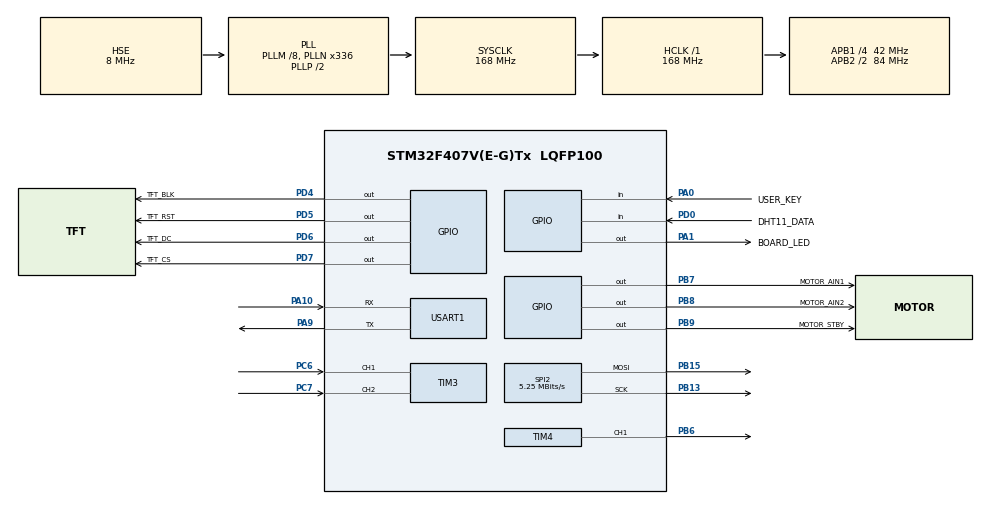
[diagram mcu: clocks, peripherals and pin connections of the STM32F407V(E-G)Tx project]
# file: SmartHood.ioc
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FREERTOS.Tasks01=defaultTask,24,256,StartDefaultTask,Default,NULL,Dynamic,NULL,NULL;sensorTask,24,256,StartSensorTask,Default,NULL,Dynamic,NULL,NULL;motorTask,24,256,StartMotorTask,Default,NULL,Dynamic,NULL,NULL
FREERTOS.configTOTAL_HEAP_SIZE=32768
Mcu.Family=STM32F4
Mcu.Name=STM32F407V(E-G)Tx
Mcu.Package=LQFP100
NVIC.PriorityGroup=NVIC_PRIORITYGROUP_4
NVIC.TIM6_DAC_IRQn=true\:15\:0\:false\:false\:true\:false\:false\:true\:true
NVIC.TimeBase=TIM6_DAC_IRQn
NVIC.TimeBaseIP=TIM6
PA0-WKUP.GPIO_Label=USER_KEY
PA0-WKUP.GPIO_PuPd=GPIO_PULLDOWN
PA0-WKUP.Signal=GPIO_Input
PA1.GPIO_Label=BOARD_LED
PA1.PinState=GPIO_PIN_SET
PA1.Signal=GPIO_Output
PA10.Mode=Asynchronous
PA10.Signal=USART1_RX
PA13.Mode=Serial_Wire
PA13.Signal=SYS_JTMS-SWDIO
PA14.Mode=Serial_Wire
PA14.Signal=SYS_JTCK-SWCLK
PA9.Mode=Asynchronous
PA9.Signal=USART1_TX
PB13.Mode=TX_Only_Simplex_Unidirect_Master
PB13.Signal=SPI2_SCK
PB15.Mode=TX_Only_Simplex_Unidirect_Master
PB15.Signal=SPI2_MOSI
PB6.Signal=S_TIM4_CH1
PB7.GPIO_Label=MOTOR_AIN1
PB7.Signal=GPIO_Output
PB8.GPIO_Label=MOTOR_AIN2
PB8.Signal=GPIO_Output
PB9.GPIO_Label=MOTOR_STBY
PB9.Signal=GPIO_Output
PC6.GPIO_PuPd=GPIO_PULLUP
PC6.Signal=S_TIM3_CH1
PC7.GPIO_PuPd=GPIO_PULLUP
PC7.Signal=S_TIM3_CH2
PD0.GPIO_Label=DHT11_DATA
PD0.GPIO_PuPd=GPIO_PULLUP
PD0.Signal=GPIO_Input
PD4.GPIO_Label=TFT_BLK
PD4.PinState=GPIO_PIN_RESET
PD4.Signal=GPIO_Output
PD5.GPIO_Label=TFT_RST
PD5.PinState=GPIO_PIN_SET
PD5.Signal=GPIO_Output
PD6.GPIO_Label=TFT_DC
PD6.PinState=GPIO_PIN_RESET
PD6.Signal=GPIO_Output
PD7.GPIO_Label=TFT_CS
PD7.PinState=GPIO_PIN_SET
PD7.Signal=GPIO_Output
PH0-OSC_IN.Mode=HSE-External-Oscillator
PH0-OSC_IN.Signal=RCC_OSC_IN
PH1-OSC_OUT.Mode=HSE-External-Oscillator
PH1-OSC_OUT.Signal=RCC_OSC_OUT
ProjectManager.HeapSize=0x400
ProjectManager.StackSize=0x800
ProjectManager.TargetToolchain=MDK-ARM V5.32
RCC.48MHZClocksFreq_Value=84000000
RCC.AHBFreq_Value=168000000
RCC.APB1CLKDivider=RCC_HCLK_DIV4
RCC.APB1Freq_Value=42000000
RCC.APB1TimFreq_Value=84000000
RCC.APB2CLKDivider=RCC_HCLK_DIV2
RCC.APB2Freq_Value=84000000
RCC.APB2TimFreq_Value=168000000
RCC.CortexFreq_Value=168000000
RCC.HCLKFreq_Value=168000000
RCC.HSE_VALUE=8000000
RCC.HSI_VALUE=16000000
RCC.LSE_VALUE=32768
RCC.PLLM=8
RCC.PLLN=336
RCC.PLLSourceVirtual=RCC_PLLSOURCE_HSE
RCC.SYSCLKFreq_VALUE=168000000
RCC.SYSCLKSource=RCC_SYSCLKSOURCE_PLLCLK
RCC.VCOOutputFreq_Value=336000000
SH.S_TIM3_CH1.0=TIM3_CH1,Encoder_Interface
SH.S_TIM3_CH2.0=TIM3_CH2,Encoder_Interface
SH.S_TIM4_CH1.0=TIM4_CH1,PWM Generation1 CH1
SPI2.BaudRatePrescaler=SPI_BAUDRATEPRESCALER_8
SPI2.CalculateBaudRate=5.25 MBits/s
SPI2.Direction=SPI_DIRECTION_2LINES
SPI2.Mode=SPI_MODE_MASTER
SPI2.VirtualType=VM_MASTER
TIM3.EncoderMode=TIM_ENCODERMODE_TI12
TIM3.IC1Filter=4
TIM3.IC2Filter=4
TIM4.Channel-PWM\ Generation1\ CH1=TIM_CHANNEL_1
TIM4.Period=4199
TIM5.Prescaler=83
USART1.VirtualMode=VM_ASYNC
VP_FREERTOS_VS_CMSIS_V2.Mode=CMSIS_V2
VP_SYS_VS_tim6.Mode=TIM6
VP_TIM5_VS_ClockSourceINT.Mode=Internal
board=custom

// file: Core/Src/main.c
/* USER CODE BEGIN Header */
/**
  ******************************************************************************
  * @file           : main.c
  * @brief          : Main program body
  ******************************************************************************
  * @attention
  *
  * Copyright (c) 2026 STMicroelectronics.
  * All rights reserved.
  *
  * This software is licensed under terms that can be found in the LICENSE file
  * in the root directory of this software component.
  * If no LICENSE file comes with this software, it is provided AS-IS.
  *
  ******************************************************************************
  */
/* USER CODE END Header */
#include "main.h"
#include "cmsis_os.h"
#include "spi.h"
#include "tim.h"
#include "usart.h"
#include "gpio.h"

void SystemClock_Config(void);
void MX_FREERTOS_Init(void);

int main(void)
{

  /* MCU Configuration--------------------------------------------------------*/

  /* Reset of all peripherals, Initializes the Flash interface and the Systick. */
  HAL_Init();

  /* Configure the system clock */
  SystemClock_Config();

  /* Initialize all configured peripherals */
  MX_GPIO_Init();
  MX_USART1_UART_Init();
  MX_SPI2_Init();
  MX_TIM5_Init();
  MX_TIM4_Init();
  MX_TIM3_Init();

  /* Init scheduler */
  osKernelInitialize();  /* Call init function for freertos objects (in cmsis_os2.c) */
  MX_FREERTOS_Init();

  /* Start scheduler */
  osKernelStart();

  /* We should never get here as control is now taken by the scheduler */

  /* Infinite loop */
  while (1)
  {

  }
}

void SystemClock_Config(void)
{
  RCC_OscInitTypeDef RCC_OscInitStruct = {0};
  RCC_ClkInitTypeDef RCC_ClkInitStruct = {0};

  /** Configure the main internal regulator output voltage
  */
  __HAL_RCC_PWR_CLK_ENABLE();
  __HAL_PWR_VOLTAGESCALING_CONFIG(PWR_REGULATOR_VOLTAGE_SCALE1);

  /** Initializes the RCC Oscillators according to the specified parameters
  * in the RCC_OscInitTypeDef structure.
  */
  RCC_OscInitStruct.OscillatorType = RCC_OSCILLATORTYPE_HSE;
  RCC_OscInitStruct.HSEState = RCC_HSE_ON;
  RCC_OscInitStruct.PLL.PLLState = RCC_PLL_ON;
  RCC_OscInitStruct.PLL.PLLSource = RCC_PLLSOURCE_HSE;
  RCC_OscInitStruct.PLL.PLLM = 8;
  RCC_OscInitStruct.PLL.PLLN = 336;
  RCC_OscInitStruct.PLL.PLLP = RCC_PLLP_DIV2;
  RCC_OscInitStruct.PLL.PLLQ = 4;
  if (HAL_RCC_OscConfig(&RCC_OscInitStruct) != HAL_OK)
  {
    Error_Handler();
  }

  /** Initializes the CPU, AHB and APB buses clocks
  */
  RCC_ClkInitStruct.ClockType = RCC_CLOCKTYPE_HCLK|RCC_CLOCKTYPE_SYSCLK
                              |RCC_CLOCKTYPE_PCLK1|RCC_CLOCKTYPE_PCLK2;
  RCC_ClkInitStruct.SYSCLKSource = RCC_SYSCLKSOURCE_PLLCLK;
  RCC_ClkInitStruct.AHBCLKDivider = RCC_SYSCLK_DIV1;
  RCC_ClkInitStruct.APB1CLKDivider = RCC_HCLK_DIV4;
  RCC_ClkInitStruct.APB2CLKDivider = RCC_HCLK_DIV2;

  if (HAL_RCC_ClockConfig(&RCC_ClkInitStruct, FLASH_LATENCY_5) != HAL_OK)
  {
    Error_Handler();
  }
}

void HAL_TIM_PeriodElapsedCallback(TIM_HandleTypeDef *htim)
{
  if (htim->Instance == TIM6)
  {
    HAL_IncTick();
  }
}

void Error_Handler(void)
{
  __disable_irq();
  while (1)
  {
  }
}

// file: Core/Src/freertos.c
/* USER CODE BEGIN Header */
/**
  ******************************************************************************
  * File Name          : freertos.c
  * Description        : Code for freertos applications
  ******************************************************************************
  * @attention
  *
  * Copyright (c) 2026 STMicroelectronics.
  * All rights reserved.
  *
  * This software is licensed under terms that can be found in the LICENSE file
  * in the root directory of this software component.
  * If no LICENSE file comes with this software, it is provided AS-IS.
  *
  ******************************************************************************
  */
/* USER CODE END Header */

#include "FreeRTOS.h"
#include "task.h"
#include "main.h"
#include "cmsis_os.h"

/* USER CODE BEGIN Includes */

/* 应用任务入口与线程安全日志初始化接口，均位于CubeMX生成区之外。 */
#include "app_tasks.h"
#include "debug_log.h"

/* USER CODE END Includes */

/* Definitions for defaultTask */
osThreadId_t defaultTaskHandle;
const osThreadAttr_t defaultTask_attributes = {
  .name = "defaultTask",
  .stack_size = 256 * 4,
  .priority = (osPriority_t) osPriorityNormal,
};
/* Definitions for sensorTask */
osThreadId_t sensorTaskHandle;
const osThreadAttr_t sensorTask_attributes = {
  .name = "sensorTask",
  .stack_size = 256 * 4,
  .priority = (osPriority_t) osPriorityNormal,
};
/* Definitions for motorTask */
osThreadId_t motorTaskHandle;
const osThreadAttr_t motorTask_attributes = {
  .name = "motorTask",
  .stack_size = 256 * 4,
  .priority = (osPriority_t) osPriorityNormal,
};

void StartDefaultTask(void *argument);
void StartSensorTask(void *argument);
void StartMotorTask(void *argument);

void MX_FREERTOS_Init(void); /* (MISRA C 2004 rule 8.1) */

void MX_FREERTOS_Init(void) {
  /* USER CODE BEGIN Init */

  /*
   * 此时内核已经初始化但任务尚未创建，适合创建日志互斥量；
   * 初始化失败时停止系统，避免任务运行后静默丢失全部日志。
   */
  if (!DebugLog_Init())
  {
    Error_Handler();
  }

  /*
   * 默认任务和电机任务启动前先创建按键事件队列。
   * 创建失败时不启动任何任务，避免PA0事件被静默丢失。
   */
  if (!App_MotorControl_Init())
  {
    Error_Handler();
  }

  /* 任务创建前建立DHT11快照互斥量，避免任务启动后竞争初始化。 */
  if (!App_SensorState_Init())
  {
    Error_Handler();
  }

  /* USER CODE END Init */

  /* Create the thread(s) */
  /* creation of defaultTask */
  defaultTaskHandle = osThreadNew(StartDefaultTask, NULL, &defaultTask_attributes);

  /* creation of sensorTask */
  sensorTaskHandle = osThreadNew(StartSensorTask, NULL, &sensorTask_attributes);

  /* creation of motorTask */
  motorTaskHandle = osThreadNew(StartMotorTask, NULL, &motorTask_attributes);

}

void StartDefaultTask(void *argument)
{
  /* USER CODE BEGIN StartDefaultTask */
	/* 将CubeMX任务入口委托给独立App层，防止重新生成覆盖业务逻辑。 */
	App_DefaultTask(argument);
  /* USER CODE END StartDefaultTask */
}

void StartSensorTask(void *argument)
{
  /* USER CODE BEGIN StartSensorTask */

  /* 将CubeMX任务入口委托给独立App层，防止重新生成覆盖业务逻辑。 */
  App_SensorTask(argument);
  /* USER CODE END StartSensorTask */
}

void StartMotorTask(void *argument)
{
  /* USER CODE BEGIN StartMotorTask */
	/*
   * 将CubeMX任务入口委托给独立App层，
   * 防止重新生成代码时覆盖编码器测速业务逻辑。
   */
  App_MotorTask(argument);
  /* USER CODE END StartMotorTask */
}
